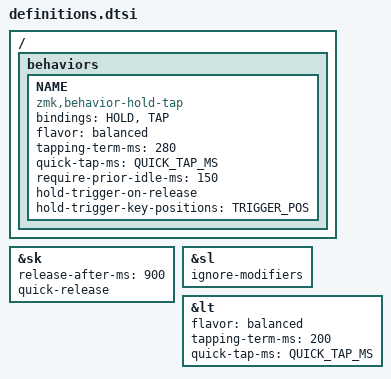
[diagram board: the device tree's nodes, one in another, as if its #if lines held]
#include <behaviors.dtsi>
#include <behaviors/num_word.dtsi> // Requires zmk-auto-layer.
#include <behaviors/unicode.dtsi> // Requires zmk-unicode.
#include <zmk-helpers/helper.h> // Requires zmk-helpers.
#include <dt-bindings/zmk/keys.h>

#ifdef CONFIG_WIRELESS
#include <dt-bindings/zmk/bt.h>
#include <dt-bindings/zmk/outputs.h>
#endif

#define DEF 0
#define NAV 1
#define FN 2
#define NUM 3
#define SYS 4
#define MOUSE 5
#define SYM 6

#define ___ &trans
#define QUICK_TAP_MS 175

&sk {
    release-after-ms = <900>;
    quick-release;
};

&sl {
    // Allow sticky modifiers to chord across sticky layers.
    ignore-modifiers;
};

&lt {
    flavor = "balanced";
    tapping-term-ms = <200>;
    quick-tap-ms = <QUICK_TAP_MS>;
};

#define MAKE_HRM(NAME, HOLD, TAP, TRIGGER_POS) \
    ZMK_HOLD_TAP(NAME, bindings = <HOLD>, <TAP>; flavor = "balanced"; \
    tapping-term-ms = <280>; quick-tap-ms = <QUICK_TAP_MS>; \
    require-prior-idle-ms = <150>; hold-trigger-on-release; \
    hold-trigger-key-positions = <TRIGGER_POS>;)

// Make home-row-mod combos tap-only (ZMK issue #544).
#define ZMK_COMBO_8(NAME, TAP, POS, LAYERS, COMBO_MS, IDLE_MS, HOLD, SIDE) \
    MAKE_HRM(hm_combo_##NAME, &kp, TAP, SIDE THUMBS) \
    ZMK_COMBO_6(NAME, &hm_combo_##NAME HOLD 0, POS, LAYERS, COMBO_MS, IDLE_MS)

#define ZYRAFT_LAYER(name, LT, RT, LM, RM, LB, RB, LH, RH) \
    ZMK_LAYER(name, LT RT LM RM LB RB LH RH)
